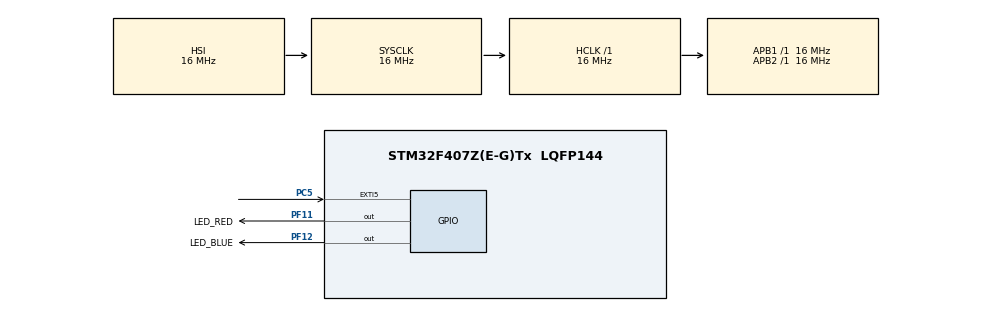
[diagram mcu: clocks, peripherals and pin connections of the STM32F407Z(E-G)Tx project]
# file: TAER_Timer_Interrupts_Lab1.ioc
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Mcu.Family=STM32F4
Mcu.Name=STM32F407Z(E-G)Tx
Mcu.Package=LQFP144
NVIC.EXTI9_5_IRQn=true\:2\:0\:true\:false\:true\:true\:true\:true
NVIC.PriorityGroup=NVIC_PRIORITYGROUP_4
NVIC.TIM2_IRQn=true\:0\:0\:false\:false\:true\:true\:true\:true
NVIC.TIM3_IRQn=true\:1\:0\:true\:false\:true\:true\:true\:true
PC5.GPIO_ModeDefaultEXTI=GPIO_MODE_IT_FALLING
PC5.GPIO_PuPd=GPIO_PULLUP
PC5.Signal=GPXTI5
PF11.GPIO_Label=LED_RED
PF11.Signal=GPIO_Output
PF12.GPIO_Label=LED_BLUE
PF12.Signal=GPIO_Output
ProjectManager.HeapSize=0x200
ProjectManager.StackSize=0x400
ProjectManager.TargetToolchain=STM32CubeIDE
RCC.48MHZClocksFreq_Value=48000000
RCC.AHBFreq_Value=16000000
RCC.APB1Freq_Value=16000000
RCC.APB1TimFreq_Value=16000000
RCC.APB2Freq_Value=16000000
RCC.APB2TimFreq_Value=16000000
RCC.CortexFreq_Value=16000000
RCC.HCLKFreq_Value=16000000
RCC.HSE_VALUE=25000000
RCC.HSI_VALUE=16000000
RCC.LSE_VALUE=32768
RCC.SYSCLKFreq_VALUE=16000000
RCC.VCOOutputFreq_Value=192000000
TIM2.Period=9999
TIM2.Prescaler=1599
TIM3.Period=4999
TIM3.Prescaler=1599
VP_TIM2_VS_ClockSourceINT.Mode=Internal
VP_TIM3_VS_ClockSourceINT.Mode=Internal
board=custom

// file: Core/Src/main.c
/* USER CODE BEGIN Header */
/**
  ******************************************************************************
  * @file           : main.c
  * @brief          : Main program body
  ******************************************************************************
  * @attention
  *
  * Copyright (c) 2026 STMicroelectronics.
  * All rights reserved.
  *
  * This software is licensed under terms that can be found in the LICENSE file
  * in the root directory of this software component.
  * If no LICENSE file comes with this software, it is provided AS-IS.
  *
  ******************************************************************************
  */
/* USER CODE END Header */
#include "main.h"

TIM_HandleTypeDef htim2;
TIM_HandleTypeDef htim3;

/* USER CODE BEGIN PV */

extern uint32_t _callfunction(uint32_t input);
uint32_t value = 0;

/*
 	 These variables are simply used as flags for the CPU to deal with. These variables are constantly checked by
 	 the main function's loop, and they simply are just for checking whether the task is ready to run or not.
 	 The reason we do not put the main interrupt code within the ISR Callback function is that the ISR Callback function
 	 should not wait for the interrupt main code to finish, hindering the ability to even interrupt at all.

 	 task_adc_ready is for TIM2, task_display_ready is for TIM3, they're all just assume for what they do.
 	 tick_count is also a flag that just counts forward whenever TIM2 interrupt fires.
*/
volatile uint8_t task_adc_ready = 0;
volatile uint8_t task_display_ready = 0;
volatile uint32_t tick_count = 0;

volatile uint32_t start = 0;
volatile uint32_t tick = 0;
volatile uint32_t maxlatency = 0;
/* USER CODE END PV */

void SystemClock_Config(void);
static void MX_GPIO_Init(void);
static void MX_TIM2_Init(void);
static void MX_TIM3_Init(void);

/* USER CODE BEGIN 0 */
/*
	HAL_TIM_PeriodElapsedCallback is an ISR Callback function that is called when a Timer interrupt occurs (TRelease), the argument or parameter
	simply holds an address to the Timer Hardware Register; TIM_HandleTypeDef is struct which holds the member htim, which
	is also holding an address of a Timer Hardware Register.

	"if(htim->Instance == TIMx)" is used to check whose timer Interrupt Service Routine(ISR) is signaling this, executes the code written
	inside it. TIM2 is RED LED, TIM3 is BLUE LED. The DEBUG_PIN is not an interrupt-based, but rather a technique for us so we can at least
	approximately measure the TISR accurately.

	Variables, such as, task_adc_ready, tick_count, and task_display_ready are simply used as flags for the CPU so that
	the ISR Callback function finishes without having to wait for the interrupt main code to finish
	(More info from the declaration of these variables above).

	volatile uint32_t start = DWT->CYCCNT is just there to record the tick when it has arrived there, and so is the "end" variable.
	volatile uint32_t tick = end - start gives you the tick starting from zero, and you must convert it to seconds, typically ticks/fAPB(hz) or
	ticks/fAPB(no hz) for microseconds.
*/
void HAL_TIM_PeriodElapsedCallback(TIM_HandleTypeDef* htim) {
	if((*htim).Instance == TIM2) {
		start = DWT->CYCCNT;
		HAL_GPIO_TogglePin(LED_RED_GPIO_Port, LED_RED_Pin);
		task_adc_ready = 1;
		tick_count++;

	}

	if((*htim).Instance == TIM3) {
		HAL_GPIO_TogglePin(LED_BLUE_GPIO_Port, LED_BLUE_Pin);
		task_display_ready = 1;
	}
}
/* USER CODE END 0 */

int main(void)
{

  /* MCU Configuration--------------------------------------------------------*/

  /* Reset of all peripherals, Initializes the Flash interface and the Systick. */
  HAL_Init();

  /* Configure the system clock */
  SystemClock_Config();

  /* Initialize all configured peripherals */
  MX_GPIO_Init();
  MX_TIM2_Init();
  MX_TIM3_Init();
  /* USER CODE BEGIN 2 */
  /*
   	   HAL_TIM_Base_Start() is a function that simply enable a timer to start, Base mode states that it's very simple and just counts and resets
   	   while "HAL_TIM_Base_Start_IT()" makes it interrupt-enabled. The argument holds an address of a timer to specify whose timer
   	   is being started, and interrupt-enabled.

   	   CoreDebug->DEMCR |= CoreDebug_DEMCR_TRCENA_Msk statement lets us use any built-in debugger, DWT->CYCCNT = 0 just resets the tick,
   	   DWT->CTRL |= DWT_CTRL_CYCCNTENA_Msk enables the DWT timer to start incrementing the tick.
  */
  HAL_TIM_Base_Start_IT(&htim2);
  HAL_TIM_Base_Start_IT(&htim3);

  CoreDebug->DEMCR |= CoreDebug_DEMCR_TRCENA_Msk;
  DWT->CYCCNT = 0;
  DWT->CTRL |= DWT_CTRL_CYCCNTENA_Msk;

  value = _callfunction(25);
  /* USER CODE END 2 */

  /* Infinite loop */
  while (1)
  {

    /* USER CODE BEGIN 3 */

	  if(task_adc_ready) {

		  task_adc_ready = 0;
		  HAL_Delay(50);
	  }

	  if(task_display_ready) {
		  task_display_ready = 0;
		  HAL_Delay(20);
		  tick = DWT->CYCCNT - start;
	  }

	  if(tick_count >= 10) {
		  tick_count = 0;
	  }
  }
  /* USER CODE END 3 */
}

void SystemClock_Config(void)
{
  RCC_OscInitTypeDef RCC_OscInitStruct = {0};
  RCC_ClkInitTypeDef RCC_ClkInitStruct = {0};

  /** Configure the main internal regulator output voltage
  */
  __HAL_RCC_PWR_CLK_ENABLE();
  __HAL_PWR_VOLTAGESCALING_CONFIG(PWR_REGULATOR_VOLTAGE_SCALE1);

  /** Initializes the RCC Oscillators according to the specified parameters
  * in the RCC_OscInitTypeDef structure.
  */
  RCC_OscInitStruct.OscillatorType = RCC_OSCILLATORTYPE_HSI;
  RCC_OscInitStruct.HSIState = RCC_HSI_ON;
  RCC_OscInitStruct.HSICalibrationValue = RCC_HSICALIBRATION_DEFAULT;
  RCC_OscInitStruct.PLL.PLLState = RCC_PLL_NONE;
  if (HAL_RCC_OscConfig(&RCC_OscInitStruct) != HAL_OK)
  {
    Error_Handler();
  }

  /** Initializes the CPU, AHB and APB buses clocks
  */
  RCC_ClkInitStruct.ClockType = RCC_CLOCKTYPE_HCLK|RCC_CLOCKTYPE_SYSCLK
                              |RCC_CLOCKTYPE_PCLK1|RCC_CLOCKTYPE_PCLK2;
  RCC_ClkInitStruct.SYSCLKSource = RCC_SYSCLKSOURCE_HSI;
  RCC_ClkInitStruct.AHBCLKDivider = RCC_SYSCLK_DIV1;
  RCC_ClkInitStruct.APB1CLKDivider = RCC_HCLK_DIV1;
  RCC_ClkInitStruct.APB2CLKDivider = RCC_HCLK_DIV1;

  if (HAL_RCC_ClockConfig(&RCC_ClkInitStruct, FLASH_LATENCY_0) != HAL_OK)
  {
    Error_Handler();
  }
}

static void MX_TIM2_Init(void)
{

  TIM_ClockConfigTypeDef sClockSourceConfig = {0};
  TIM_MasterConfigTypeDef sMasterConfig = {0};

  htim2.Instance = TIM2;
  htim2.Init.Prescaler = 1599;
  htim2.Init.CounterMode = TIM_COUNTERMODE_UP;
  htim2.Init.Period = 9999;
  htim2.Init.ClockDivision = TIM_CLOCKDIVISION_DIV1;
  htim2.Init.AutoReloadPreload = TIM_AUTORELOAD_PRELOAD_DISABLE;
  if (HAL_TIM_Base_Init(&htim2) != HAL_OK)
  {
    Error_Handler();
  }
  sClockSourceConfig.ClockSource = TIM_CLOCKSOURCE_INTERNAL;
  if (HAL_TIM_ConfigClockSource(&htim2, &sClockSourceConfig) != HAL_OK)
  {
    Error_Handler();
  }
  sMasterConfig.MasterOutputTrigger = TIM_TRGO_RESET;
  sMasterConfig.MasterSlaveMode = TIM_MASTERSLAVEMODE_DISABLE;
  if (HAL_TIMEx_MasterConfigSynchronization(&htim2, &sMasterConfig) != HAL_OK)
  {
    Error_Handler();
  }

}

static void MX_TIM3_Init(void)
{

  TIM_ClockConfigTypeDef sClockSourceConfig = {0};
  TIM_MasterConfigTypeDef sMasterConfig = {0};

  htim3.Instance = TIM3;
  htim3.Init.Prescaler = 1599;
  htim3.Init.CounterMode = TIM_COUNTERMODE_UP;
  htim3.Init.Period = 4999;
  htim3.Init.ClockDivision = TIM_CLOCKDIVISION_DIV1;
  htim3.Init.AutoReloadPreload = TIM_AUTORELOAD_PRELOAD_DISABLE;
  if (HAL_TIM_Base_Init(&htim3) != HAL_OK)
  {
    Error_Handler();
  }
  sClockSourceConfig.ClockSource = TIM_CLOCKSOURCE_INTERNAL;
  if (HAL_TIM_ConfigClockSource(&htim3, &sClockSourceConfig) != HAL_OK)
  {
    Error_Handler();
  }
  sMasterConfig.MasterOutputTrigger = TIM_TRGO_RESET;
  sMasterConfig.MasterSlaveMode = TIM_MASTERSLAVEMODE_DISABLE;
  if (HAL_TIMEx_MasterConfigSynchronization(&htim3, &sMasterConfig) != HAL_OK)
  {
    Error_Handler();
  }

}

static void MX_GPIO_Init(void)
{
  GPIO_InitTypeDef GPIO_InitStruct = {0};

  /* GPIO Ports Clock Enable */
  __HAL_RCC_GPIOC_CLK_ENABLE();
  __HAL_RCC_GPIOF_CLK_ENABLE();

  /*Configure GPIO pin Output Level */
  HAL_GPIO_WritePin(GPIOF, LED_RED_Pin|LED_BLUE_Pin, GPIO_PIN_RESET);

  /*Configure GPIO pin : PC5 */
  GPIO_InitStruct.Pin = GPIO_PIN_5;
  GPIO_InitStruct.Mode = GPIO_MODE_IT_FALLING;
  GPIO_InitStruct.Pull = GPIO_PULLUP;
  HAL_GPIO_Init(GPIOC, &GPIO_InitStruct);

  /*Configure GPIO pins : LED_RED_Pin LED_BLUE_Pin */
  GPIO_InitStruct.Pin = LED_RED_Pin|LED_BLUE_Pin;
  GPIO_InitStruct.Mode = GPIO_MODE_OUTPUT_PP;
  GPIO_InitStruct.Pull = GPIO_NOPULL;
  GPIO_InitStruct.Speed = GPIO_SPEED_FREQ_LOW;
  HAL_GPIO_Init(GPIOF, &GPIO_InitStruct);

  /* EXTI interrupt init*/
  HAL_NVIC_SetPriority(EXTI9_5_IRQn, 2, 0);
  HAL_NVIC_EnableIRQ(EXTI9_5_IRQn);

}

/* USER CODE BEGIN 4 */
void HAL_GPIO_EXTI_Callback(uint16_t GPIO_Pin) {
	if(GPIO_Pin == GPIO_PIN_5) {
		HAL_GPIO_TogglePin(LED_RED_GPIO_Port, LED_RED_Pin);
		HAL_GPIO_TogglePin(LED_BLUE_GPIO_Port, LED_BLUE_Pin);
	}
}
/* USER CODE END 4 */

void Error_Handler(void)
{
  __disable_irq();
  while (1)
  {
  }
}
